VERSION "All_Common"

NS_ :

BS_:

BU_: PCM UNKNOWN VSA

BO_ 145 VSA_0x091: 8 VSA
 SG_ YAW_RATE_SENSOR : 7|10@0+ (1,0) [0|1023] "raw"  PCM
 SG_ UNKNOWN_1 : 13|8@0+ (1,0) [0|255] ""  PCM
 SG_ LATERAL_ACCELERATION_SENSOR : 19|10@0+ (1,0) [0|1023] "raw"  PCM
 SG_ UNKNOWN_2 : 20|2@1+ (1,0) [0|3] ""  PCM
 SG_ LONGITUDINAL_ACCELERATION_SENSOR : 25|10@0+ (1,0) [0|1023] "raw"  PCM
 SG_ UNKNOWN_3 : 40|4@1+ (1,0) [0|15] ""  PCM
 SG_ LONGITUDINAL_FAULT_SUMMARY : 44|1@1+ (1,0) [0|1] ""  PCM
 SG_ LATERAL_FAULT_SUMMARY : 45|1@1+ (1,0) [0|1] ""  PCM
 SG_ MONITOR_SUMMARY_0 : 46|1@1+ (1,0) [0|1] ""  PCM
 SG_ YAW_FAULT_SUMMARY : 47|1@1+ (1,0) [0|1] ""  PCM
 SG_ MONITOR_CONDITION_2 : 48|1@1+ (1,0) [0|1] ""  PCM
 SG_ MONITOR_SUMMARY_1 : 49|1@1+ (1,0) [0|1] ""  PCM
 SG_ UNKNOWN_4 : 50|2@1+ (1,0) [0|3] ""  PCM
 SG_ LONGITUDINAL_FAULT_CONDITION : 52|1@1+ (1,0) [0|1] ""  PCM
 SG_ LATERAL_FAULT_CONDITION : 53|1@1+ (1,0) [0|1] ""  PCM
 SG_ MONITOR_CONDITION_0 : 54|1@1+ (1,0) [0|1] ""  PCM
 SG_ YAW_FAULT_CONDITION : 55|1@1+ (1,0) [0|1] ""  PCM
 SG_ CHECKSUM : 56|4@1+ (1,0) [0|15] ""  PCM
 SG_ COUNTER : 60|2@1+ (1,0) [0|3] ""  PCM
 SG_ STATUS_BIT_1 : 62|1@1+ (1,0) [0|1] ""  PCM
 SG_ SCALAR_NOT_READY : 63|1@1+ (1,0) [0|1] ""  PCM
VAL_ 145 SCALAR_NOT_READY 1 "NOT_READY" ;

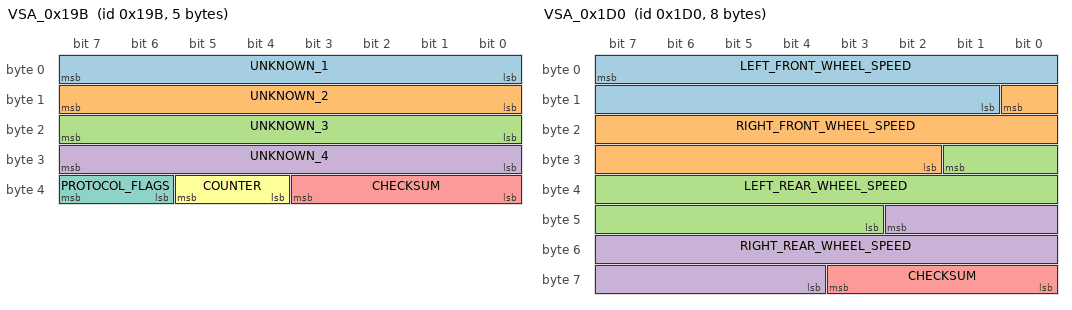
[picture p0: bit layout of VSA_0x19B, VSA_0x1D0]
BO_ 411 VSA_0x19B: 5 VSA
 SG_ UNKNOWN_1 : 0|8@1+ (1,0) [0|255] ""  UNKNOWN
 SG_ UNKNOWN_2 : 8|8@1+ (1,0) [0|255] ""  UNKNOWN
 SG_ UNKNOWN_3 : 16|8@1+ (1,0) [0|255] ""  UNKNOWN
 SG_ UNKNOWN_4 : 24|8@1+ (1,0) [0|255] ""  UNKNOWN
 SG_ CHECKSUM : 32|4@1+ (1,0) [0|15] ""  UNKNOWN
 SG_ COUNTER : 36|2@1+ (1,0) [0|3] ""  UNKNOWN
 SG_ PROTOCOL_FLAGS : 38|2@1+ (1,0) [0|3] ""  UNKNOWN

BO_ 420 VSA_0x1A4: 8 VSA
 SG_ MASTER_CYLINDER_PRESSURE : 3|12@0+ (1,0) [0|4095] "raw"  PCM
 SG_ PRESSURE_FAULT_CONDITION : 4|1@1+ (1,0) [0|1] ""  PCM
 SG_ PRESSURE_FAULT_SUMMARY : 5|1@1+ (1,0) [0|1] ""  PCM
 SG_ CONTROLLER_STATE_3 : 6|1@1+ (1,0) [0|1] ""  PCM
 SG_ CONTROLLER_STATE_5 : 7|1@1+ (1,0) [0|1] ""  PCM
 SG_ VSA_INTERVENTION_ACTIVE : 16|1@1+ (1,0) [0|1] ""  PCM
 SG_ ABS_INTERVENTION_ACTIVE : 17|1@1+ (1,0) [0|1] ""  PCM
 SG_ STATUS_BIT_1 : 18|1@1+ (1,0) [0|1] ""  PCM
 SG_ STATUS_BIT_2 : 19|1@1+ (1,0) [0|1] ""  PCM
 SG_ IDLE_STOP_INHIBIT_VSACASEN : 20|1@1+ (1,0) [0|1] ""  PCM
 SG_ STATUS_BIT_3 : 21|1@1+ (1,0) [0|1] ""  PCM
 SG_ CONTROLLER_STATE_QUALIFIED : 22|1@1+ (1,0) [0|1] ""  PCM
 SG_ COMPUTER_BRAKING_TBD : 23|1@1+ (1,0) [0|1] ""  PCM
 SG_ SNAPSHOT_STATUS_0 : 24|1@1+ (1,0) [0|1] ""  PCM
 SG_ SNAPSHOT_STATUS_1 : 25|1@1+ (1,0) [0|1] ""  PCM
 SG_ SNAPSHOT_STATUS_2 : 26|1@1+ (1,0) [0|1] ""  PCM
 SG_ VSA_SYSTEM_PROBLEM_REQUEST_REF : 27|1@1+ (1,0) [0|1] ""  PCM
 SG_ VSA_DISABLED_TBD : 28|1@1+ (1,0) [0|1] ""  PCM
 SG_ VSA_PRIORITY_WARNING_REQUEST_REF : 29|1@1+ (1,0) [0|1] ""  PCM
 SG_ ABS_WARNING_REQUEST_REF : 30|1@1+ (1,0) [0|1] ""  PCM
 SG_ BRAKE_SYSTEM_PROBLEM_REQUEST_REF : 31|1@1+ (1,0) [0|1] ""  PCM
 SG_ PHASE_ENTRY_LATCH : 32|1@1+ (1,0) [0|1] ""  PCM
 SG_ TRAILER_STABILITY_ASSIST_PROBLEM_REQUEST_REF : 33|1@1+ (1,0) [0|1] ""  PCM
 SG_ VSA_WATCHDOG_REFRESH_REQUEST : 34|1@1+ (1,0) [0|1] ""  PCM
 SG_ CONTROLLER_TERM_STATUS : 35|1@1+ (1,0) [0|1] ""  PCM
 SG_ UNKNOWN_1 : 36|4@1+ (1,0) [0|15] ""  PCM
 SG_ UNKNOWN_2 : 40|4@1+ (1,0) [0|15] ""  PCM
 SG_ IDLE_STOP_BRAKE_TRANSITION_INPUT_REF : 44|1@1+ (1,0) [0|1] ""  PCM
 SG_ BRAKE_HOLD_ENABLED_REF : 45|1@1+ (1,0) [0|1] ""  PCM
 SG_ BRAKE_HOLD_ACTIVE_REF : 46|1@1+ (1,0) [0|1] ""  PCM
 SG_ STATUS_BIT_8 : 47|1@1+ (1,0) [0|1] ""  PCM
 SG_ HILL_START_ASSIST_PROBLEM_REQUEST_REF : 48|1@1+ (1,0) [0|1] ""  PCM
 SG_ CONTROLLER_QUALIFIED : 49|1@1+ (1,0) [0|1] ""  PCM
 SG_ CONTROLLER_STATE_6 : 50|1@1+ (1,0) [0|1] ""  PCM
 SG_ CONTROLLER_STATE_10 : 51|1@1+ (1,0) [0|1] ""  PCM
 SG_ BRAKE_HOLD_RELATED_TBD : 52|1@1+ (1,0) [0|1] ""  PCM
 SG_ STATUS_BIT_9 : 53|1@1+ (1,0) [0|1] ""  PCM
 SG_ STATUS_BIT_10 : 54|1@1+ (1,0) [0|1] ""  PCM
 SG_ STATUS_BIT_11 : 55|1@1+ (1,0) [0|1] ""  PCM
 SG_ CHECKSUM : 56|4@1+ (1,0) [0|15] ""  PCM
 SG_ COUNTER : 60|2@1+ (1,0) [0|3] ""  PCM
 SG_ STATUS_BIT_12 : 62|1@1+ (1,0) [0|1] ""  PCM
 SG_ CONTROLLER_ACTIVITY_QUALIFIED : 63|1@1+ (1,0) [0|1] ""  PCM
VAL_ 420 IDLE_STOP_INHIBIT_VSACASEN 0 "NORMAL" 1 "INHIBITED" ;
CM_ SG_ 420 BRAKE_HOLD_ACTIVE_REF "Both brake hold flags can assert at startup.";

BO_ 426 VSA_0x1AA: 8 VSA
 SG_ UNKNOWN_1 : 7|16@0- (1,0) [-32768|32767] "raw"  PCM
 SG_ REQUEST_SOURCE_MODE : 16|2@1+ (1,0) [0|3] ""  PCM
 SG_ UNKNOWN_2 : 18|2@1+ (1,0) [0|3] ""  PCM
 SG_ REQUEST_CATEGORY : 20|4@1+ (1,0) [0|15] ""  PCM
 SG_ UNKNOWN_3 : 24|3@1+ (1,0) [0|7] ""  PCM
 SG_ STATUS_BIT_1 : 27|1@1+ (1,0) [0|1] ""  PCM
 SG_ UNKNOWN_4 : 28|4@1+ (1,0) [0|15] ""  PCM
 SG_ UNKNOWN_5 : 32|8@1+ (1,0) [0|255] ""  PCM
 SG_ CONTROLLER_ZERO_STATE : 40|1@1+ (1,0) [0|1] ""  PCM
 SG_ STATUS_BIT_2 : 41|1@1+ (1,0) [0|1] ""  PCM
 SG_ STATUS_BIT_3 : 42|1@1+ (1,0) [0|1] ""  PCM
 SG_ IDLE_STOP_INHIBIT_STARTING_ASSIST_BRAKE : 43|1@1+ (1,0) [0|1] ""  PCM
 SG_ UNKNOWN_6 : 44|2@1+ (1,0) [0|3] ""  PCM
 SG_ STATUS_BIT_4 : 46|1@1+ (1,0) [0|1] ""  PCM
 SG_ IDLE_STOP_INHIBIT_ABS_VSA_UNIT : 47|1@1+ (1,0) [0|1] ""  PCM
 SG_ UNKNOWN_7 : 48|8@1+ (1,0) [0|255] ""  PCM
 SG_ CHECKSUM : 56|4@1+ (1,0) [0|15] ""  PCM
 SG_ COUNTER : 60|2@1+ (1,0) [0|3] ""  PCM
 SG_ SECONDARY_REQUEST_ACTIVE : 62|1@1+ (1,0) [0|1] ""  PCM
 SG_ STATUS_BIT_5 : 63|1@1+ (1,0) [0|1] ""  PCM
VAL_ 426 IDLE_STOP_INHIBIT_ABS_VSA_UNIT 0 "NORMAL" 1 "INHIBITED" ;
VAL_ 426 IDLE_STOP_INHIBIT_STARTING_ASSIST_BRAKE 0 "INHIBITED" 1 "NORMAL" ;
VAL_ 426 REQUEST_SOURCE_MODE 0 "NO_SELECTED_REQUEST" 1 "SECONDARY_REQUEST" 2 "PRIMARY_REQUEST" 3 "NO_SELECTED_REQUEST" ;

BO_ 432 VSA_0x1B0: 7 VSA
 SG_ BRAKE_DIAGNOSTIC_QUALIFIED : 0|1@1+ (1,0) [0|1] ""  PCM
 SG_ LATERAL_FAULT_SUMMARY : 1|1@1+ (1,0) [0|1] ""  PCM
 SG_ LONGITUDINAL_FAULT_SUMMARY : 2|1@1+ (1,0) [0|1] ""  PCM
 SG_ LATERAL_FAULT_CONDITION : 3|1@1+ (1,0) [0|1] ""  PCM
 SG_ LONGITUDINAL_FAULT_CONDITION : 4|1@1+ (1,0) [0|1] ""  PCM
 SG_ BRAKE_DIAGNOSTIC_CONDITION : 5|1@1+ (1,0) [0|1] ""  PCM
 SG_ BRAKE_DIAGNOSTIC_STATUS : 6|1@1+ (1,0) [0|1] ""  PCM
 SG_ STATUS_BIT_1 : 7|1@1+ (1,0) [0|1] ""  PCM
 SG_ PHASE_B_SELECTED : 8|1@1+ (1,0) [0|1] ""  PCM
 SG_ PHASE_B_ALTERNATE : 9|1@1+ (1,0) [0|1] ""  PCM
 SG_ PHASE_A_SELECTED : 10|1@1+ (1,0) [0|1] ""  PCM
 SG_ PHASE_A_ALTERNATE : 11|1@1+ (1,0) [0|1] ""  PCM
 SG_ CAPTURE_COUNT_ACTIVITY : 12|1@1+ (1,0) [0|1] ""  PCM
 SG_ STEERING_FAULT_SUMMARY : 13|1@1+ (1,0) [0|1] ""  PCM
 SG_ YAW_FAULT_SUMMARY : 14|1@1+ (1,0) [0|1] ""  PCM
 SG_ CAPTURE_INHIBIT : 15|1@1+ (1,0) [0|1] ""  PCM
 SG_ UNKNOWN_1 : 16|8@1+ (1,0) [0|255] ""  PCM
 SG_ UNKNOWN_2 : 24|8@1+ (1,0) [0|255] ""  PCM
 SG_ STEERING_FAULT_CONDITION : 32|1@1+ (1,0) [0|1] ""  PCM
 SG_ YAW_FAULT_CONDITION : 33|1@1+ (1,0) [0|1] ""  PCM
 SG_ PRESSURE_FAULT_CONDITION : 34|1@1+ (1,0) [0|1] ""  PCM
 SG_ RIGHT_FRONT_WHEEL_FAULT_CONDITION : 35|1@1+ (1,0) [0|1] ""  PCM
 SG_ LEFT_FRONT_WHEEL_FAULT_CONDITION : 36|1@1+ (1,0) [0|1] ""  PCM
 SG_ RIGHT_REAR_WHEEL_FAULT_CONDITION : 37|1@1+ (1,0) [0|1] ""  PCM
 SG_ LEFT_REAR_WHEEL_FAULT_CONDITION : 38|1@1+ (1,0) [0|1] ""  PCM
 SG_ WHEEL_FAULT_SUMMARY : 39|1@1+ (1,0) [0|1] ""  PCM
 SG_ PHASE_5_QUALIFIED : 40|1@1+ (1,0) [0|1] ""  PCM
 SG_ CONTROLLER_STATE_QUALIFIED : 41|1@1+ (1,0) [0|1] ""  PCM
 SG_ REQUEST_AVAILABLE : 42|2@1+ (1,0) [0|3] ""  PCM
 SG_ CONTROL_LATCH_1 : 44|1@1+ (1,0) [0|1] ""  PCM
 SG_ CONTROL_LATCH_0 : 45|1@1+ (1,0) [0|1] ""  PCM
 SG_ CONTROL_LATCH_3 : 46|1@1+ (1,0) [0|1] ""  PCM
 SG_ CONTROL_LATCH_2 : 47|1@1+ (1,0) [0|1] ""  PCM
 SG_ CHECKSUM : 48|4@1+ (1,0) [0|15] ""  PCM
 SG_ COUNTER : 52|2@1+ (1,0) [0|3] ""  PCM
 SG_ PROTOCOL_FLAGS : 54|2@1+ (1,0) [0|3] ""  PCM
VAL_ 432 REQUEST_AVAILABLE 1 "AVAILABLE" ;

BO_ 464 VSA_0x1D0: 8 VSA
 SG_ LEFT_FRONT_WHEEL_SPEED : 7|15@0+ (0.00993422,0) [0|325.51458674] "km/h"  PCM
 SG_ RIGHT_FRONT_WHEEL_SPEED : 8|15@0+ (0.00993422,0) [0|325.51458674] "km/h"  PCM
 SG_ LEFT_REAR_WHEEL_SPEED : 25|15@0+ (0.00993422,0) [0|325.51458674] "km/h"  PCM
 SG_ RIGHT_REAR_WHEEL_SPEED : 42|15@0+ (0.00993422,0) [0|325.51458674] "km/h"  PCM
 SG_ CHECKSUM : 56|4@1+ (1,0) [0|15] ""  PCM

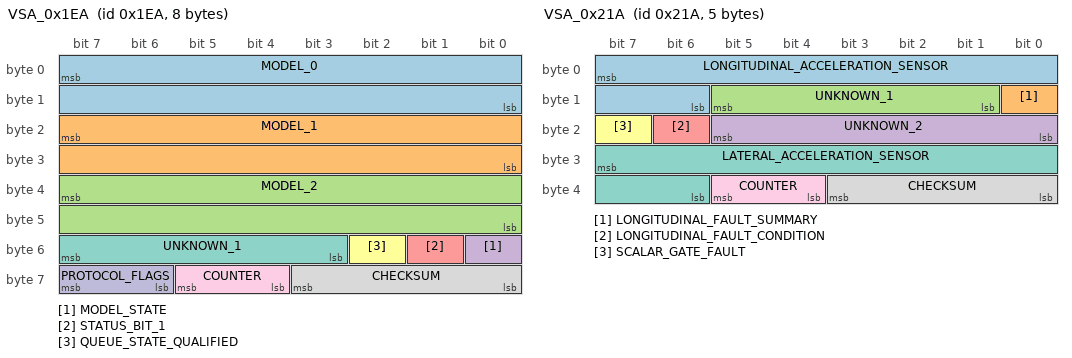
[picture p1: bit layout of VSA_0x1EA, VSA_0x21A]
BO_ 490 VSA_0x1EA: 8 VSA
 SG_ MODEL_0 : 7|16@0+ (1,0) [0|65535] "raw"  UNKNOWN
 SG_ MODEL_1 : 23|16@0+ (1,0) [0|65535] "raw"  UNKNOWN
 SG_ MODEL_2 : 39|16@0+ (1,0) [0|65535] "raw"  UNKNOWN
 SG_ MODEL_STATE : 48|1@1+ (1,0) [0|1] ""  UNKNOWN
 SG_ STATUS_BIT_1 : 49|1@1+ (1,0) [0|1] ""  UNKNOWN
 SG_ QUEUE_STATE_QUALIFIED : 50|1@1+ (1,0) [0|1] ""  UNKNOWN
 SG_ UNKNOWN_1 : 51|5@1+ (1,0) [0|31] ""  UNKNOWN
 SG_ CHECKSUM : 56|4@1+ (1,0) [0|15] ""  UNKNOWN
 SG_ COUNTER : 60|2@1+ (1,0) [0|3] ""  UNKNOWN
 SG_ PROTOCOL_FLAGS : 62|2@1+ (1,0) [0|3] ""  UNKNOWN

BO_ 538 VSA_0x21A: 5 VSA
 SG_ LONGITUDINAL_ACCELERATION_SENSOR : 7|10@0+ (1,0) [0|1023] "raw"  PCM
 SG_ LONGITUDINAL_FAULT_SUMMARY : 8|1@1+ (1,0) [0|1] ""  PCM
 SG_ UNKNOWN_1 : 9|5@1+ (1,0) [0|31] ""  PCM
 SG_ UNKNOWN_2 : 16|6@1+ (1,0) [0|63] ""  PCM
 SG_ LONGITUDINAL_FAULT_CONDITION : 22|1@1+ (1,0) [0|1] ""  PCM
 SG_ SCALAR_GATE_FAULT : 23|1@1+ (1,0) [0|1] ""  PCM
 SG_ LATERAL_ACCELERATION_SENSOR : 31|10@0+ (1,0) [0|1023] "raw"  PCM
 SG_ CHECKSUM : 32|4@1+ (1,0) [0|15] ""  PCM
 SG_ COUNTER : 36|2@1+ (1,0) [0|3] ""  PCM

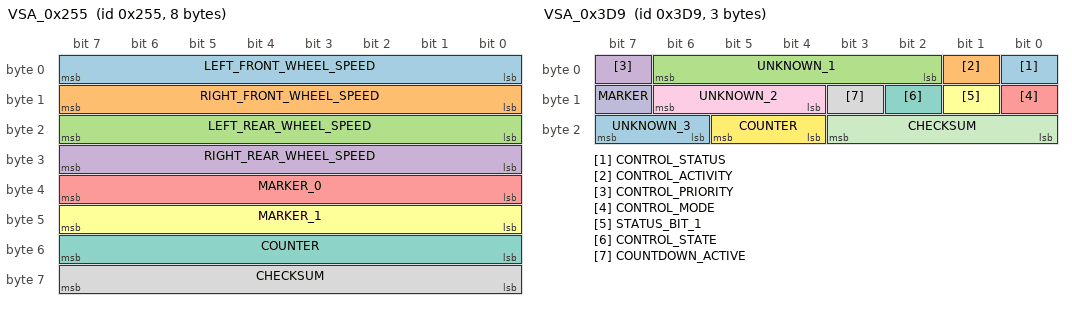
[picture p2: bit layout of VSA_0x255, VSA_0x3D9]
BO_ 597 VSA_0x255: 8 VSA
 SG_ LEFT_FRONT_WHEEL_SPEED : 0|8@1+ (1,0) [0|255] "raw"  UNKNOWN
 SG_ RIGHT_FRONT_WHEEL_SPEED : 8|8@1+ (1,0) [0|255] "raw"  UNKNOWN
 SG_ LEFT_REAR_WHEEL_SPEED : 16|8@1+ (1,0) [0|255] "raw"  UNKNOWN
 SG_ RIGHT_REAR_WHEEL_SPEED : 24|8@1+ (1,0) [0|255] "raw"  UNKNOWN
 SG_ MARKER_0 : 32|8@1+ (1,0) [0|255] ""  UNKNOWN
 SG_ MARKER_1 : 40|8@1+ (1,0) [0|255] ""  UNKNOWN
 SG_ COUNTER : 48|8@1+ (1,0) [0|255] ""  UNKNOWN
 SG_ CHECKSUM : 56|8@1+ (1,0) [0|255] ""  UNKNOWN

BO_ 985 VSA_0x3D9: 3 VSA
 SG_ CONTROL_STATUS : 0|1@1+ (1,0) [0|1] ""  UNKNOWN
 SG_ CONTROL_ACTIVITY : 1|1@1+ (1,0) [0|1] ""  UNKNOWN
 SG_ UNKNOWN_1 : 2|5@1+ (1,0) [0|31] ""  UNKNOWN
 SG_ CONTROL_PRIORITY : 7|1@1+ (1,0) [0|1] ""  UNKNOWN
 SG_ CONTROL_MODE : 8|1@1+ (1,0) [0|1] ""  UNKNOWN
 SG_ STATUS_BIT_1 : 9|1@1+ (1,0) [0|1] ""  UNKNOWN
 SG_ CONTROL_STATE : 10|1@1+ (1,0) [0|1] ""  UNKNOWN
 SG_ COUNTDOWN_ACTIVE : 11|1@1+ (1,0) [0|1] ""  UNKNOWN
 SG_ UNKNOWN_2 : 12|3@1+ (1,0) [0|7] ""  UNKNOWN
 SG_ MARKER : 15|1@1+ (1,0) [0|1] ""  UNKNOWN
 SG_ CHECKSUM : 16|4@1+ (1,0) [0|15] ""  UNKNOWN
 SG_ COUNTER : 20|2@1+ (1,0) [0|3] ""  UNKNOWN
 SG_ UNKNOWN_3 : 22|2@1+ (1,0) [0|3] ""  UNKNOWN

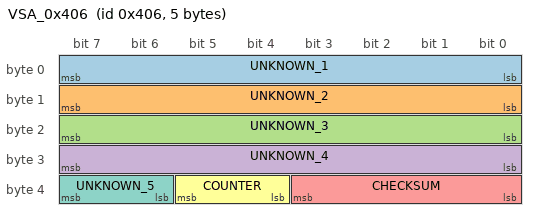
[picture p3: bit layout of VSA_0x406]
BO_ 1030 VSA_0x406: 5 VSA
 SG_ UNKNOWN_1 : 0|8@1+ (1,0) [0|255] ""  UNKNOWN
 SG_ UNKNOWN_2 : 8|8@1+ (1,0) [0|255] ""  UNKNOWN
 SG_ UNKNOWN_3 : 16|8@1+ (1,0) [0|255] ""  UNKNOWN
 SG_ UNKNOWN_4 : 24|8@1+ (1,0) [0|255] ""  UNKNOWN
 SG_ CHECKSUM : 32|4@1+ (1,0) [0|15] ""  UNKNOWN
 SG_ COUNTER : 36|2@1+ (1,0) [0|3] ""  UNKNOWN
 SG_ UNKNOWN_5 : 38|2@1+ (1,0) [0|3] ""  UNKNOWN
